# MCXN947_cm33_core0 register map
Vendor: nxp.com; File version: 1.0
CPU: CM33 r2p0, little endian, MPU, FPU, VTOR, 3 interrupt priority bits
Registers are 32-bit, read-write, reset 0x0 unless marked. A register's access mark holds for its fields unless they carry their own. Offsets are from the block's base; [hi:lo] are bit positions; {n}, {i} and the like mark numbered series; 'fields as' and 'values as' point back to an identical list.

## SYSCON0 (part 1 of 2) — SYSCON
Base 0x40000000
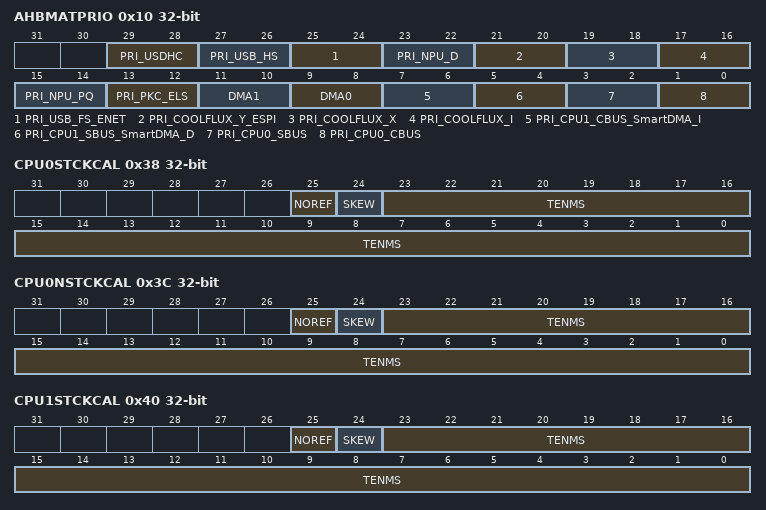
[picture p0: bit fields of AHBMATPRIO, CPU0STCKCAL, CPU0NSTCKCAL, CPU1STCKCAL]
0x10 AHBMATPRIO — AHB Matrix Priority Control
  [all] fields
    {v}=LEVEL{v} (v=0..3)
  [29:28] PRI_USDHC — USDHC bus master priority level
  [27:26] PRI_USB_HS — USB-HS bus master priority level
  [25:24] PRI_USB_FS_ENET — USB-FS and ENET bus master priority level
  [23:22] PRI_NPU_D — NPU D bus master priority level
  [21:20] PRI_COOLFLUX_Y_ESPI — CoolFlux Y bus master priority level
  [19:18] PRI_COOLFLUX_X — CoolFlux X bus master priority level
  [17:16] PRI_COOLFLUX_I — CoolFlux I bus master priority level
  [15:14] PRI_NPU_PQ — NPU O bus and Powerquad bus master priority level
  [13:12] PRI_PKC_ELS — PKC and ELS bus master priority level
  [11:10] DMA1 — DMA1 controller bus master priority level
  [9:8] DMA0 — DMA0 controller bus master priority level
  [7:6] PRI_CPU1_CBUS_SmartDMA_I — CPU1 C-AHB/SmartDMA-I bus master priority level
  [5:4] PRI_CPU1_SBUS_SmartDMA_D — CPU1 S-AHB/SmartDMA-D bus master priority level
  [3:2] PRI_CPU0_SBUS — CPU0 S-AHB bus master priority level
  [1:0] PRI_CPU0_CBUS — CPU0 C-AHB bus master priority level
0x38 CPU0STCKCAL — Secure CPU0 System Tick Calibration
  [25] NOREF — Whether the device provides a reference clock to the processor.
    0=YES_REF (Reference clock is provided); 1=NO_REF (No reference clock is provided)
  [24] SKEW — Whether the TENMS value is exact.
    0=EXACT (TENMS value is exact); 1=INEXACT (TENMS value is not exact or not given)
  [23:0] TENMS — Reload value for 10 ms (100 Hz) timing, subject to system clock skew errors. If the value reads as zero, the calibration value is not known.
0x3C CPU0NSTCKCAL — Non-Secure CPU0 System Tick Calibration
  [25] NOREF — Indicates whether the device provides a reference clock to the processor.
    values as CPU0STCKCAL.NOREF
  [24] SKEW — Indicates whether the TENMS value is exact.
    values as CPU0STCKCAL.SKEW
  [23:0] TENMS — Reload value for 10 ms (100 Hz) timing, subject to system clock skew errors. If the value reads as zero, the calibration value is not known.
0x40 CPU1STCKCAL — System tick calibration for CPU1
  [25] NOREF — Indicates whether the device provides a reference clock to the processor. 0 = reference clock is provided; 1 = no reference clock is provided.
  [24] SKEW — Indicates whether the TENMS value is exact: 0 = TENMS value is exact; 1 = TENMS value is not exact or not given.
  [23:0] TENMS — Reload value for 10 ms (100 Hz) timing, subject to system clock skew errors. If the value reads as zero, the calibration value is not known.
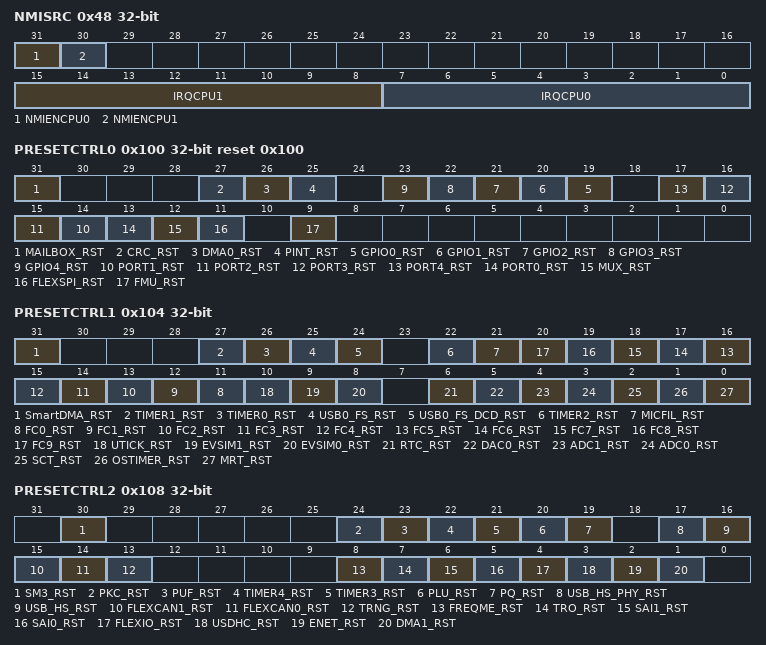
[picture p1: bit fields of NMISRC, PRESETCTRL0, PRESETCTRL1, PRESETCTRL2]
0x48 NMISRC — NMI Source Select
  [31] NMIENCPU0 — Enables the Non-Maskable Interrupt (NMI) source selected by IRQCPU0.
    0=DISABLE; 1=ENABLE
  [30] NMIENCPU1 — Enables the Non-Maskable Interrupt (NMI) source selected by IRQCPU1.
    0=DISABLE; 1=ENABLE
  [15:8] IRQCPU1 — The IRQ number of the interrupt that acts as the Non-Maskable Interrupt (NMI) for CPU1, if enabled by NMIENCPU1.
  [7:0] IRQCPU0 — The IRQ number of the interrupt that acts as the Non-Maskable Interrupt (NMI) for CPU0, if enabled by NMIENCPU0.
0x100 PRESETCTRL0 reset 0x100 (reset mask 0xCEFB13FC) — Peripheral Reset Control 0
  [all] fields
    0=RELEASED (Block is not reset); 1=ASSERTED (Block is reset)
  [31] MAILBOX_RST — Inter-CPU communication Mailbox reset control
  [27] CRC_RST — CRC reset control
  [26] DMA0_RST — DMA0 reset control
  [25] PINT_RST — PINT reset control
  [n+19] GPIO{n}_RST (n=0..4) — GPIO{n} reset control
  [n+13] PORT{n}_RST (n=1..4) — PORT{n} reset control
  [13] PORT0_RST — PORT0 controller reset control
  [12] MUX_RST — INPUTMUX reset control
  [11] FLEXSPI_RST — FlexSPI reset control
  [9] FMU_RST — Flash management unit reset control
0x104 PRESETCTRL1 (reset mask 0xAFFFFF3F) — Peripheral Reset Control 1
  [all] fields
    0=RELEASED (Block is not reset); 1=ASSERTED (Block is reset)
  [31] SmartDMA_RST — SmartDMA reset control
  [27] TIMER1_RST — CTIMER1 reset control
  [26] TIMER0_RST — CTIMER0 reset control
  [25] USB0_FS_RST — USB FS reset control
  [24] USB0_FS_DCD_RST — USB FS DCD reset control
  [22] TIMER2_RST — CTIMER2 reset control
  [21] MICFIL_RST — MICFIL reset control
  [n+11] FC{n}_RST (n=0..9) — LP_FLEXCOMM{n} reset control
  [10] UTICK_RST — UTICK reset control
  [9] EVSIM1_RST — EVSIM1 reset control
  [8] EVSIM0_RST — EVSIM0 reset control
  [6] RTC_RST — RTC reset control
  [5] DAC0_RST — DAC0 reset control
  [4] ADC1_RST — ADC1 reset control
  [3] ADC0_RST — ADC0 reset control
  [2] SCT_RST — SCT reset control
  [1] OSTIMER_RST — OS Event Timer reset control
  [0] MRT_RST — MRT reset control
0x108 PRESETCTRL2 — Peripheral Reset Control 2
  [all] fields
    0=RELEASED (Block is not reset); 1=ASSERTED (Block is reset)
  [30] SM3_RST — SM3 reset control
  [24] PKC_RST — PKC reset control
  [23] PUF_RST — PUF reset control
  [22] TIMER4_RST — CTIMER4 reset control
  [21] TIMER3_RST — CTIMER3 reset control
  [20] PLU_RST — PLU reset control
  [19] PQ_RST — PowerQuad reset control
  [17] USB_HS_PHY_RST — USB HS PHY reset control
  [16] USB_HS_RST — USB HS reset control
  [15] FLEXCAN1_RST — CAN1 reset control
  [14] FLEXCAN0_RST — CAN0 reset control
  [13] TRNG_RST — TRNG reset control
  [8] FREQME_RST — FREQME reset control
  [7] TRO_RST — TRO reset control
  [6] SAI1_RST — SAI1 reset control
  [5] SAI0_RST — SAI0 reset control
  [4] FLEXIO_RST — FLEXIO reset control
  [3] USDHC_RST — uSDHC reset control
  [2] ENET_RST — Ethernet reset control
  [1] DMA1_RST — DMA1 reset control
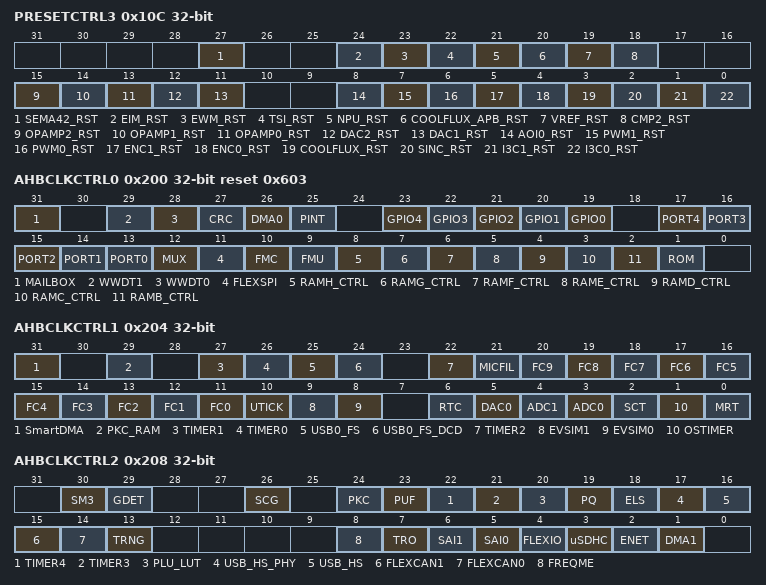
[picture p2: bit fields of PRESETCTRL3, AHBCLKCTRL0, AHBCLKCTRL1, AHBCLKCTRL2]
0x10C PRESETCTRL3 — Peripheral Reset Control 3
  [all] fields
    0=RELEASED (Block is not reset); 1=ASSERTED (Block is reset)
  [27] SEMA42_RST — Semaphore reset control
  [24] EIM_RST — EIM reset control
  [23] EWM_RST — EWM reset control
  [22] TSI_RST — TSI reset control
  [21] NPU_RST — NPU reset control
  [20] COOLFLUX_APB_RST — CoolFlux APB reset control
  [19] VREF_RST — VREF reset control
  [18] CMP2_RST — CMP2 reset control
  [15] OPAMP2_RST — OPAMP2 reset control
  [14] OPAMP1_RST — OPAMP1 reset control
  [13] OPAMP0_RST — OPAMP0 reset control
  [12] DAC2_RST — DAC2 reset control
  [11] DAC1_RST — DAC1 reset control
  [8] AOI0_RST — AOI0 reset control
  [7] PWM1_RST — PWM1 reset control
  [6] PWM0_RST — PWM0 reset control
  [5] ENC1_RST — ENC1 reset control
  [4] ENC0_RST — ENC0 reset control
  [3] COOLFLUX_RST — CoolFlux reset control
  [2] SINC_RST — SINC reset control
  [1] I3C1_RST — I3C1 reset control
  [0] I3C0_RST — I3C0 reset control
{0x120+4i} PRESETCTRLSET[{i}] (i=0..3) wo — Peripheral Reset Control Set
  [31:0] DATA — Data array value, refer to corresponding position in PRESETCTRLn.
{0x140+4i} PRESETCTRLCLR[{i}] (i=0..3) wo — Peripheral Reset Control Clear
  fields as PRESETCTRLSET[0]
0x200 AHBCLKCTRL0 reset 0x603 — AHB Clock Control 0
  [all] fields
    0=DISABLE (Disables clock); 1=ENABLE (Enables clock)
  [31] MAILBOX — Enables the clock for the Inter CPU communication Mailbox.
  [29] WWDT1 — Enables the clock for WWDT1
  [28] WWDT0 — Enables the clock for WWDT0
  [27] CRC — Enables the clock for CRC
  [26] DMA0 — Enables the clock for DMA0
  [25] PINT — Enables the clock for PINT
  [n+19] GPIO{n} (n=0..4) — Enables the clock for GPIO{n}
  [n+13] PORT{n} (n=1..4) — Enables the clock for PORT{n}
  [13] PORT0 — Enables the clock for PORT0 controller
  [12] MUX — Enables the clock for INPUTMUX
  [11] FLEXSPI — Enables the clock for FlexSPI
  [10] FMC — Enables the clock for the Flash Memory Controller
  [9] FMU — Enables the clock for the Flash Management Unit
  [8] RAMH_CTRL — Enables the clock for the RAMH Controller
  [7] RAMG_CTRL — Enables the clock for the RAMG Controller
  [6] RAMF_CTRL — Enables the clock for the RAMF Controller
  [5] RAME_CTRL — Enables the clock for the RAME Controller
  [4] RAMD_CTRL — Enables the clock for the RAMD Controller
  [3] RAMC_CTRL — Enables the clock for the RAMC Controller
  [2] RAMB_CTRL — Enables the clock for the RAMB Controller
  [1] ROM — Enables the clock for the ROM
0x204 AHBCLKCTRL1 — AHB Clock Control 1
  [all] fields
    0=DISABLE (Disables clock); 1=ENABLE (Enables clock)
  [31] SmartDMA — Enables the clock for SmartDMA
  [29] PKC_RAM — Enables the clock for PKC RAM
  [27] TIMER1 — Enables the clock for CTIMER1
  [26] TIMER0 — Enables the clock for CTIMER0
  [25] USB0_FS — Enables the clock for USB-FS
  [24] USB0_FS_DCD — Enables the clock for USB-FS DCD
  [22] TIMER2 — Enables the clock for CTIMER2
  [21] MICFIL — Enables the clock for MICFIL
  [n+11] FC{n} (n=0..9) — Enables the clock for LP_FLEXCOMM{n}
  [10] UTICK — Enables the clock for UTICK
  [9] EVSIM1 — Enables the clock for EVSIM1
  [8] EVSIM0 — Enables the clock for EVSIM0
  [6] RTC — Enables the clock for RTC
  [5] DAC0 — Enables the clock for DAC0
  [4] ADC1 — Enables the clock for ADC1
  [3] ADC0 — Enables the clock for ADC0
  [2] SCT — Enables the clock for SCT
  [1] OSTIMER — Enables the clock for the OS Event Timer
  [0] MRT — Enables the clock for MRT
0x208 AHBCLKCTRL2 — AHB Clock Control 2
  [30] SM3 — Enables the clock for SM3
    0=DISABLE (Disables clock); 1=ENABLE (Enables clock)
  [29] GDET — Enables the clock for GDET0 and GDET1
    0=DISABLE (Disables clock); 1=ENABLE (Enables clock)
  [26] SCG — Enables the clock for SCG
    0=DISABLE (Disables clock); 1=ENABLE (Enables clock)
  [24] PKC — Enables the clock for PKC
    0=DISABLE (Disables clock); 1=ENABLE (Enables clock)
  [23] PUF — Enables the clock for PUF
    0=DISABLE (Disables clock); 1=ENABLE (Enables clock)
  [22] TIMER4 — Enables the clock for CTIMER4
    0=DISABLE (Disables clock); 1=ENABLE (Enables clock)
  [21] TIMER3 — Enables the clock for CTIMER3
    0=DISABLE (Disables clock); 1=ENABLE (Enables clock)
  [20] PLU_LUT — Enables the clock for PLU_LUT
    0=DISABLE (Disables clock); 1=ENABLE (Enables clock)
  [19] PQ — Enables the clock for Powerquad
    0=DISABLE (Disables clock); 1=ENABLE (Enables clock)
  [18] ELS — Enables the clock for ELS
    0=DISABLE (Disables clock); 1=ENABLE (Enables clock)
  [17] USB_HS_PHY — Enables the clock for USB HS PHY
    0=DISABLE (Disables clock); 1=ENABLE (Enables clock)
  [16] USB_HS — Enables the clock for USB HS
    0=DISABLE (Disables clock); 1=ENABLE (Enables clock)
  [15] FLEXCAN1 — Enables the clock for FLEXCAN1
    0=DISABLE (Disables clock); 1=ENABLE (Enables clock)
  [14] FLEXCAN0 — Enables the clock for FLEXCAN0
    0=DISABLE (Disables clock); 1=ENABLE (Enables clock)
  [13] TRNG — Enables the clock for TRNG
    0=DISABLE (Disables clock); 1=ENABLE (Enables clock)
  [8] FREQME — Enables the clock for the Frequency meter
    0=DISABLE (Disables clock); 1=ENABLE (Enables clock)
  [7] TRO — Enables the clock for TRO
    0=DISABLE (Disables clock); 1=ENABLE (Enables clock)
  [6] SAI1 — Enables the clock for SAI1
    0=DISABLE (Disables clock); 1=ENABLE (Enables clock)
  [5] SAI0 — Enables the clock for SAI0
    0=DISABLE (Disables clock); 1=ENABLE (Enables clock)
  [4] FLEXIO — Enables the clock for Flexio
    0=DISABLE (Disables clock); 1=ENABLE (Enable clock)
  [3] uSDHC — Enables the clock for uSDHC
    0=DISABLE (Disables clock); 1=ENABLE (Enables clock)
  [2] ENET — Enables the clock for Ethernet
    0=DISABLE (Disables clock); 1=ENABLE (Enables clock)
  [1] DMA1 — Enables the clock for DMA1
    0=DISABLE (Disables clock); 1=ENABLE (Enables clock)
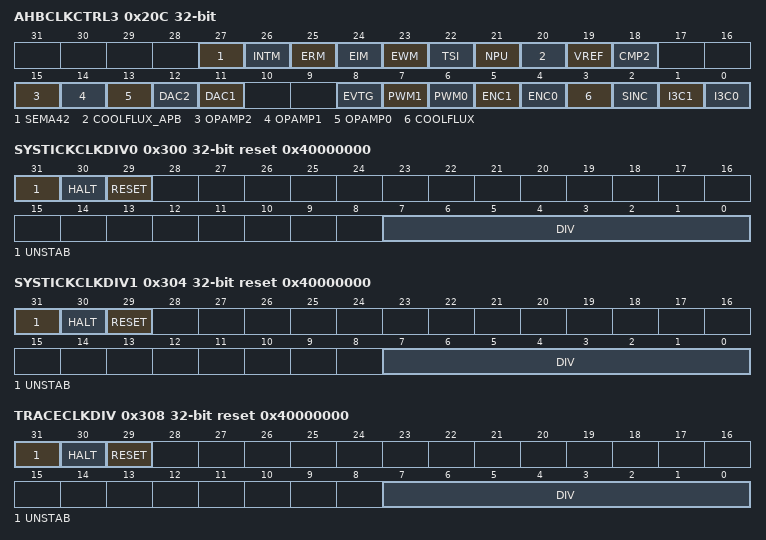
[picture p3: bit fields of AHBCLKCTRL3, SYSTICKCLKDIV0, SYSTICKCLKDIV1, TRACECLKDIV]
0x20C AHBCLKCTRL3 — AHB Clock Control 3
  [27] SEMA42 — Enables the clock for Semaphore
    0=DISABLE (Disables clock); 1=ENABLE (Enables clock)
  [26] INTM — Enables the clock for INTM
    0=DISABLE (Disables clock); 1=ENABLE (Enables clock)
  [25] ERM — Enables the clock for ERM
    0=DISABLE (Disables clock); 1=ENABLE (Enables clock)
  [24] EIM — Enables the clock for EIM
    0=DISABLE (Disables clock); 1=ENABLE (Enables clock)
  [23] EWM — Enables the clock for EWM
    0=DISABLE (Disables clock); 1=ENABLE (Enables clock)
  [22] TSI — Enables the clock for TSI
    0=DISABLE (Disables clock); 1=ENABLE (Enables clock)
  [21] NPU — Enables the clock for NPU
    0=DISABLE (Disables clock); 1=ENABLE (Enables clock)
  [20] COOLFLUX_APB — Enables the clock for CoolFlux APB
    0=DISABLE (Disables clock); 1=ENABLE (Enables clock (CoolFlux needs to be properly programmed before the clock enabled.))
  [19] VREF — Enables the clock for VREF
    0=DISABLE (Disables clock); 1=ENABLE (Enables clock)
  [18] CMP2 — Enables the clock for CMP2
    0=DISABLE (Disables clock); 1=ENABLE (Enables clock)
  [15] OPAMP2 — Enables the clock for OPAMP2
    0=DISABLE (Disables clock); 1=ENABLE (Enables clock)
  [14] OPAMP1 — Enables the clock for OPAMP1
    0=DISABLE (Disables clock); 1=ENABLE (Enables clock)
  [13] OPAMP0 — Enables the clock for OPAMP0
    0=DISABLE (Disables clock); 1=ENABLE (Enables clock)
  [12] DAC2 — Enables the clock for DAC2
    0=DISABLE (Disables clock); 1=ENABLE (Enables clock)
  [11] DAC1 — Enables the clock for DAC1
    0=DISABLE (Disables clock); 1=ENABLE (Enables clock)
  [8] EVTG — Enables the clock for EVTG
    0=DISABLE (Disables clock); 1=ENABLE (Enables clock)
  [7] PWM1 — Enables the clock for PWM1
    0=DISABLE (Disables clock); 1=ENABLE (Enables clock)
  [6] PWM0 — Enables the clock for PWM0
    0=DISABLE (Disables clock); 1=ENABLE (Enables clock)
  [5] ENC1 — Enables the clock for ENC1
    0=DISABLE (Disables clock); 1=ENABLE (Enables clock)
  [4] ENC0 — Enables the clock for ENC0
    0=DISABLE (Disables clock); 1=ENABLE (Enables clock)
  [3] COOLFLUX — Enables the clock for CoolFlux
    0=DISABLE (Disables clock); 1=ENABLE (Enables clock)
  [2] SINC — Enables the clock for SINC
    0=DISABLE (Disables clock); 1=ENABLE (Enables clock)
  [1] I3C1 — Enables the clock for I3C1
    0=DISABLE (Disables clock); 1=ENABLE (Enables clock)
  [0] I3C0 — Enables the clock for I3C0
    0=DISABLE (Disables clock); 1=ENABLE (Enables clock)
{0x220+4i} AHBCLKCTRLSET[{i}] (i=0..3) wo — AHB Clock Control Set
  [31:0] DATA — Data array value
{0x240+4i} AHBCLKCTRLCLR[{i}] (i=0..3) wo — AHB Clock Control Clear
  [31:0] DATA — Data array value
0x260 SYSTICKCLKSEL0 reset 0x7 — CPU0 System Tick Timer Source Select
  [2:0] SEL — Selects the System Tick Timer for CPU0 source
    0=ENUM_0x0 (SYSTICKCLKDIV0 output); 1=ENUM_0x1 (Clk 1 MHz clock); 2=ENUM_0x2 (LP Oscillator clock); {v}=ENUM_{0x0+v} (No clock) (v=3..7)
0x264 SYSTICKCLKSEL1 reset 0x7 — CPU1 System Tick Timer Source Select
  [2:0] SEL — Selects the System Tick Timer for CPU1 source.
    0=ENUM_0x0 (SYSTICKCLKDIV1 output); 1=ENUM_0x1 (Clk 1 MHz clock); 2=ENUM_0x2 (LP Oscillator clock); {v}=ENUM_{0x0+v} (No clock) (v=3..7)
0x268 TRACECLKSEL reset 0x7 — Trace Clock Source Select
  [2:0] SEL — Selects the trace clock source.
    0=ENUM_0x0 (TRACECLKDIV output); 1=ENUM_0x1 (Clk 1 MHz clock); 2=ENUM_0x2 (LP Oscillator clock); {v}=ENUM_{0x0+v} (No clock) (v=3..7)
{0x26C+4i} CTIMERCLKSEL[{i}] (i=0..4) reset 0xF — CTIMER Clock Source Select
  [3:0] SEL — Selects the CTIMER clock source.
    0=ENUM_0x0 (FRO_1M clock); 1=ENUM_0x1 (PLL0 clock); 2=ENUM_0x2 (PLL1_clk0 clock); 3=ENUM_0x3 (FRO_HF clock); 4=ENUM_0x4 (FRO 12MHz clock); 5=ENUM_0x5 (SAI0 MCLK IN clock); 6=ENUM_0x6 (LP Oscillator clock); 7=ENUM_0x7 (No clock); 8=ENUM_0x8 (SAI1 MCLK IN clock); 9=ENUM_0x9 (SAI0 TX_BCLK clock); 10=ENUM_0xA (SAI0 RX_BCLK clock); 11=ENUM_0xB (SAI1 TX_BCLK clock); 12=ENUM_0xC (SAI1 RX_BCLK clock); 13=ENUM_0xD (No clock); 14=ENUM_0xE (No clock); 15=ENUM_0xF (No clock)
0x288 CLKOUTSEL reset 0xF — CLKOUT Clock Source Select
  [3:0] SEL — Selects the CLKOUT clock source.
    0=ENUM_0x0 (Main clock (main_clk)); 1=ENUM_0x1 (PLL0 clock (pll0_clk)); 2=ENUM_0x2 (CLKIN clock (clk_in)); 3=ENUM_0x3 (FRO_HF clock (fro_hf)); 4=ENUM_0x4 (FRO 12 MHz clock (fro_12m)); 5=ENUM_0x5 (PLL1_clk0 clock (pll1_clk)); 6=ENUM_0x6 (LP Oscillator clock (lp_osc)); 7=ENUM_0x7 (USB PLL clock (usb_pll_clk)); {v}=ENUM_{0x0+v} (No clock) (v=8..15)
0x2A4 ADC0CLKSEL reset 0x7 — ADC0 Clock Source Select
  [2:0] SEL — Selects the ADC0 clock source.
    0=ENUM_0x0 (No clock); 1=ENUM_0x1 (PLL0 clock); 2=ENUM_0x2 (FRO_HF clock); 3=ENUM_0x3 (FRO 12 MHz clock); 4=ENUM_0x4 (Clk_in); 5=ENUM_0x5 (PLL1_clk0 clock); 6=ENUM_0x6 (USB PLL clock); 7=ENUM_0x7 (No clock)
0x2A8 USB0CLKSEL reset 0x7 — USB-FS Clock Source Select
  [2:0] SEL — Selects the USB-FS clock source.
    0=ENUM_0x0 (No clock); 1=ENUM_0x1 (PLL0 clock); 2=ENUM_0x2 (No clock); 3=ENUM_0x3 (Clk 48 MHz clock); 4=ENUM_0x4 (Clk_in); 5=ENUM_0x5 (PLL1_clk0 clock); 6=ENUM_0x6 (USB PLL clock); 7=ENUM_0x7 (No clock)
{0x2B0+4i} FCCLKSEL[{i}] (i=0..9) reset 0x7 — LP_FLEXCOMM Clock Source Select for Fractional Rate Divider
  [2:0] SEL — Selects the LP_FLEXCOMM clock source for Fractional Rate Divider.
    0=ENUM_0x0 (No clock); 1=ENUM_0x1 (PLL divided clock); 2=ENUM_0x2 (FRO 12 MHz clock); 3=ENUM_0x3 (fro_hf_div clock); 4=ENUM_0x4 (CLK_1MHz clock); 5=ENUM_0x5 (USB PLL clock); 6=ENUM_0x6 (LP Oscillator clock); 7=ENUM_0x7 (No clock)
0x2F0 SCTCLKSEL reset 0xF — SCTimer/PWM Clock Source Select
  [3:0] SEL — Selects the SCTimer/PWM clock source.
    0=ENUM_0x0 (No clock); 1=ENUM_0x1 (PLL0 clock); 2=ENUM_0x2 (CLKIN clock); 3=ENUM_0x3 (FRO_HF clock); 4=ENUM_0x4 (PLL1_clk0 clock); 5=ENUM_0x5 (SAI0 MCLK_IN clock); 6=ENUM_0x6 (USB PLL clock); 7=ENUM_0x7 (No clock); 8=ENUM_0x8 (SAI1 MCLK_IN clock); {v}=ENUM_{0x0+v} (No clock) (v=9..15)
0x300 SYSTICKCLKDIV0 reset 0x40000000 — CPU0 System Tick Timer Divider
  [31] UNSTAB ro — Divider status flag
    0=STABLE (Divider clock is stable); 1=ONGOING (Clock frequency is not stable)
  [30] HALT — Halts the divider counter
    0=RUN (Divider clock is running); 1=HALT (Divider clock is stopped)
  [29] RESET — Resets the divider counter
    0=RELEASED (Divider is not reset); 1=ASSERTED (Divider is reset.)
  [7:0] DIV — Clock divider value
0x304 SYSTICKCLKDIV1 reset 0x40000000 — CPU1 System Tick Timer Divider
  [31] UNSTAB ro — Divider status flag
    values as SYSTICKCLKDIV0.UNSTAB
  [30] HALT — Halts the divider counter
    values as SYSTICKCLKDIV0.HALT
  [29] RESET — Resets the divider counter
    0=RELEASED (Divider is not reset); 1=ASSERTED (Divider is reset)
  [7:0] DIV — Clock divider value
0x308 TRACECLKDIV reset 0x40000000 — TRACE Clock Divider
  fields as SYSTICKCLKDIV1
0x350 TSICLKSEL reset 0x7 — TSI Function Clock Source Select
  [2:0] SEL — Selects the TSI function clock source.
    0=ENUM_0x0 (No clock); 1=ENUM_0x1 (No clock); 2=ENUM_0x2 (clk_in); 3=ENUM_0x3 (No clock); 4=ENUM_0x4 (FRO_12Mhz clock); 5=ENUM_0x5 (No clock); 6=ENUM_0x6 (No clock); 7=ENUM_0x7 (No clock)
0x360 SINCFILTCLKSEL reset 0x7 — SINC FILTER Function Clock Source Select
  [2:0] SEL — Selects the SINC FILTER function clock source.
    0=ENUM_0x0 (No clock); 1=ENUM_0x1 (PLL0 clock); 2=ENUM_0x2 (clk_in); 3=ENUM_0x3 (FRO_HF clock); 4=ENUM_0x4 (FRO_12Mhz clock); 5=ENUM_0x5 (PLL1_clk0 clock); 6=ENUM_0x6 (USB PLL clock); 7=ENUM_0x7 (No clock)
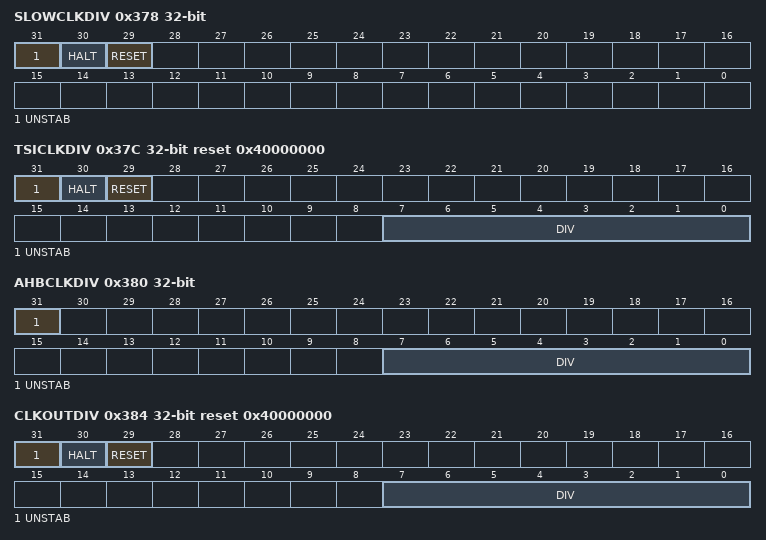
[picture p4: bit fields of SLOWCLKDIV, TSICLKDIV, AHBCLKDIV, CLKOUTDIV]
0x378 SLOWCLKDIV — SLOW_CLK Clock Divider
  [31] UNSTAB ro — Divider status flag
    values as SYSTICKCLKDIV0.UNSTAB
  [30] HALT — Halts the divider counter
    values as SYSTICKCLKDIV0.HALT
  [29] RESET — Resets the divider counter
    values as SYSTICKCLKDIV1.RESET
0x37C TSICLKDIV reset 0x40000000 — TSI Function Clock Divider
  [31] UNSTAB ro — Divider status flag
    values as SYSTICKCLKDIV0.UNSTAB
  [30] HALT — Halts the divider counter
    values as SYSTICKCLKDIV0.HALT
  [29] RESET — Resets the divider counter
    values as SYSTICKCLKDIV1.RESET
  [7:0] DIV — Clock divider value:
0x380 AHBCLKDIV — System Clock Divider
  [31] UNSTAB ro — Divider status flag
    values as SYSTICKCLKDIV0.UNSTAB
  [7:0] DIV — Clock divider value
0x384 CLKOUTDIV reset 0x40000000 — CLKOUT Clock Divider
  fields as SYSTICKCLKDIV1
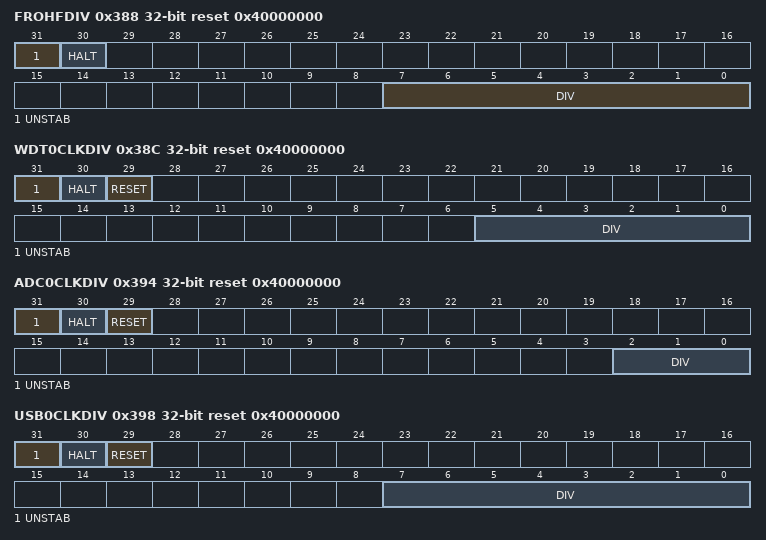
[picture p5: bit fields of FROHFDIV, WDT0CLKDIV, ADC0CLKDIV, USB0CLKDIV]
0x388 FROHFDIV reset 0x40000000 — FRO_HF_DIV Clock Divider
  [31] UNSTAB ro — Divider status flag
    values as SYSTICKCLKDIV0.UNSTAB
  [30] HALT ro — Halts the divider counter
    0=RUN (Divider clock is running, this bit is set to 0 when the register is written.); 1=HALT (Divider clock is stopped)
  [7:0] DIV — Clock divider value
0x38C WDT0CLKDIV reset 0x40000000 — WDT0 Clock Divider
  [31] UNSTAB ro — Divider status flag
    values as SYSTICKCLKDIV0.UNSTAB
  [30] HALT — Halts the divider counter
    values as SYSTICKCLKDIV0.HALT
  [29] RESET — Resets the divider counter
    values as SYSTICKCLKDIV1.RESET
  [5:0] DIV — Clock divider value
0x394 ADC0CLKDIV reset 0x40000000 — ADC0 Clock Divider
  [31] UNSTAB ro — Divider status flag
    values as SYSTICKCLKDIV0.UNSTAB
  [30] HALT — Halts the divider counter
    values as SYSTICKCLKDIV0.HALT
  [29] RESET — Resets the divider counter
    values as SYSTICKCLKDIV1.RESET
  [2:0] DIV — Clock divider value
0x398 USB0CLKDIV reset 0x40000000 — USB-FS Clock Divider
  fields as SYSTICKCLKDIV1
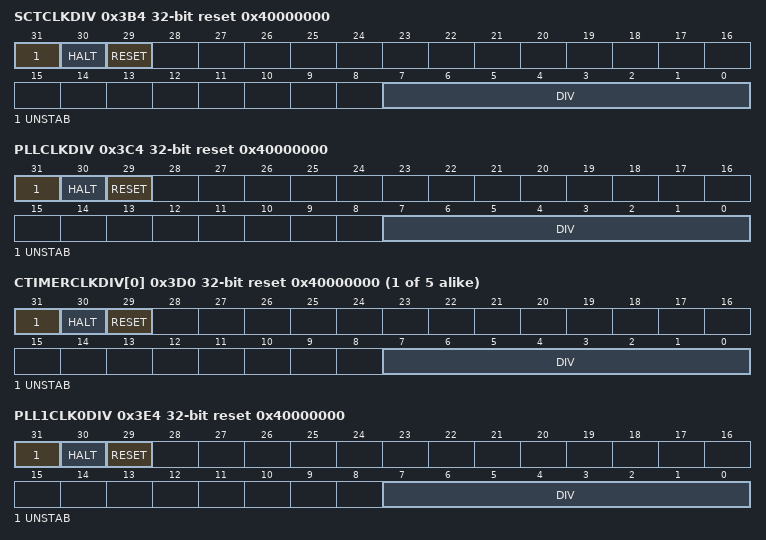
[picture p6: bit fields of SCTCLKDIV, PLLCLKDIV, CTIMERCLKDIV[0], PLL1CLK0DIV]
0x3B4 SCTCLKDIV reset 0x40000000 — SCT/PWM Clock Divider
  fields as SYSTICKCLKDIV1
0x3C4 PLLCLKDIV reset 0x40000000 — PLL Clock Divider
  fields as SYSTICKCLKDIV1
{0x3D0+4i} CTIMERCLKDIV[{i}] (i=0..4) reset 0x40000000 — CTimer Clock Divider
  [31] UNSTAB — Divider status flag
    0=ENABLE (Stable divider clock); 1=DISABLE (Unstable clock frequency)
  [30] HALT — Halts the divider counter
    0=ENABLE (Divider clock is running); 1=DISABLE (Divider clock has stopped)
  [29] RESET — Resets the divider counter
    0=DISABLE (Divider is not reset); 1=ENABLE (Divider is reset)
  [7:0] DIV — Clock divider value
0x3E4 PLL1CLK0DIV reset 0x40000000 — PLL1 Clock 0 Divider
  fields as SYSTICKCLKDIV1
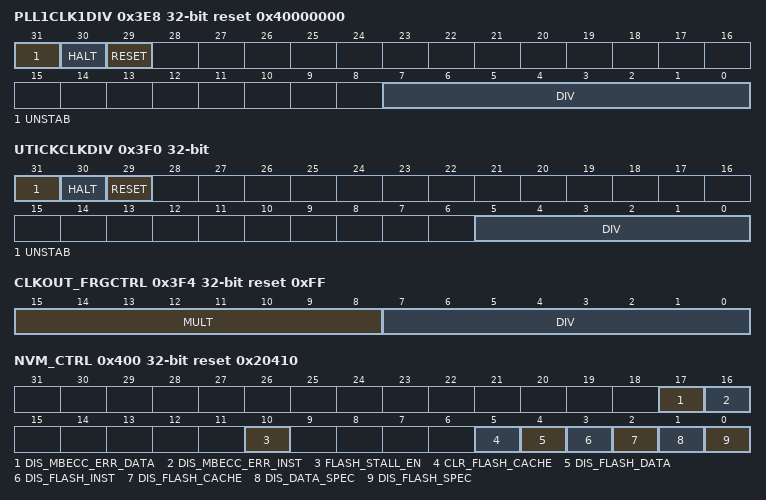
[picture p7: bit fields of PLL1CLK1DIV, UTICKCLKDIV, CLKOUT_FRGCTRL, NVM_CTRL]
0x3E8 PLL1CLK1DIV reset 0x40000000 — PLL1 Clock 1 Divider
  fields as SYSTICKCLKDIV1
0x3F0 UTICKCLKDIV — UTICK Clock Divider
  fields as WDT0CLKDIV
0x3F4 CLKOUT_FRGCTRL reset 0xFF — CLKOUT FRG Control
  [15:8] MULT — Numerator value
  [7:0] DIV — Divider value
0x3FC CLKUNLOCK — Clock Configuration Unlock
  [0] UNLOCK — Controls clock configuration registers access (for example, xxxDIV, xxxSEL)
    0=ENABLE (Updates are allowed to all clock configuration registers); 1=FREEZE (Freezes all clock configuration registers update)
0x400 NVM_CTRL reset 0x20410 — NVM Control
  [17] DIS_MBECC_ERR_DATA — Bus error on data multi-bit ECC error control If DIS_MBECC_ERR_DATA and/or DIS_MBECC_INST are set, then speculation will not be enabled, even if this bit is cleared
    0=ENABLE (Enables bus error on multi-bit ECC error for data); 1=DISABLE (Disables bus error on multi-bit ECC error for data)
  [16] DIS_MBECC_ERR_INST — Bus error on instruction multi-bit ECC error control If DIS_MBECC_ERR_DATA and/or DIS_MBECC_INST are set, then speculation will not be enabled, even if this bit is cleared
    0=ENABLE (Enables bus error on multi-bit ECC error for instruction); 1=DISABLE (Disables bus error on multi-bit ECC error for instruction)
  [10] FLASH_STALL_EN — FLASH stall on busy control
    0=ENABLE (No stall on FLASH busy); 1=DISABLE (Stall on FLASH busy)
  [5] CLR_FLASH_CACHE — Clear flash cache control
    0=ENABLE (No clear flash cache); 1=DISABLE (Clears flash cache)
  [4] DIS_FLASH_DATA — Flash data cache control
    0=ENABLE (Enables flash data cache when DIS_FLASH_CACHE=0); 1=DISABLE (Disables flash data cache)
  [3] DIS_FLASH_INST — Flash instruction cache control
    0=ENABLE (Enables flash instruction cache when DIS_FLASH_CACHE=0); 1=DISABLE (Disables flash instruction cache)
  [2] DIS_FLASH_CACHE — Flash cache control
    0=ENABLE (Enables flash cache); 1=DISABLE (Disables flash cache)
  [1] DIS_DATA_SPEC — Flash data speculation control
    0=ENABLE (Enables data speculation); 1=DISABLE (Disables data speculation)
  [0] DIS_FLASH_SPEC — Flash speculation control
    0=ENABLE (Enables flash speculation); 1=DISABLE (Disables flash speculation)
0x404 ROMCR — ROM Wait State
  [0] ROM_WAIT — ROM waiting Arm core and other masters for one cycle
    0=DISABLE (Disabled); 1=Enabled
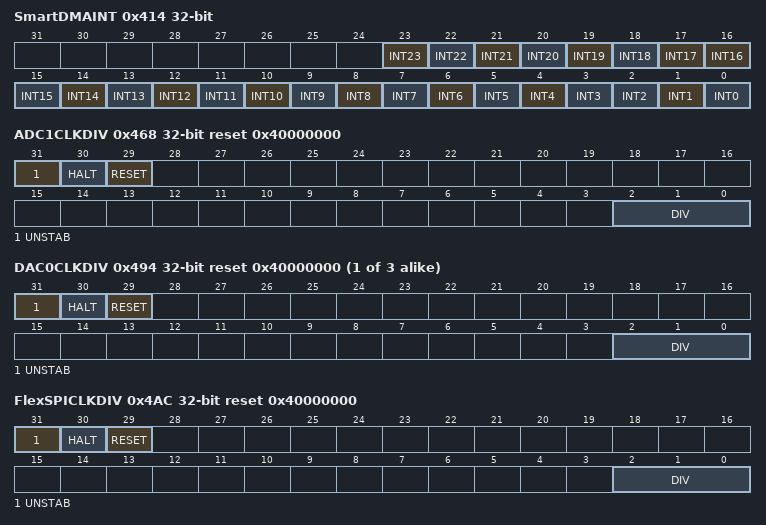
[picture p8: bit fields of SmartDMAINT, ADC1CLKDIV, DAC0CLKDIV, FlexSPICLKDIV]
0x414 SmartDMAINT — SmartDMA Interrupt Hijack
  [all] fields
    0=DISABLE; 1=ENABLE
  [23] INT23 — SmartDMA hijack NVIC IRQ77
  [22] INT22 — SmartDMA hijack NVIC IRQ67
  [21] INT21 — SmartDMA hijack NVIC IRQ66
  [20] INT20 — SmartDMA hijack NVIC IRQ51
  [19] INT19 — SmartDMA hijack NVIC IRQ50
  [18] INT18 — SmartDMA hijack NVIC IRQ47
  [17] INT17 — SmartDMA hijack NVIC IRQ45
  [n] INT{n} (n=3..16) — SmartDMA hijack NVIC IRQ{n+26}
  [2] INT2 — SmartDMA hijack NVIC IRQ18
  [1] INT1 — SmartDMA hijack NVIC IRQ17
  [0] INT0 — SmartDMA hijack NVIC IRQ1
0x464 ADC1CLKSEL reset 0x7 — ADC1 Clock Source Select
  [2:0] SEL — Selects the ADC1 clock source
    0=ENUM_0x0 (No clock); 1=ENUM_0x1 (PLL0 clock); 2=ENUM_0x2 (FRO_HF clock); 3=ENUM_0x3 (FRO 12 MHz clock); 4=ENUM_0x4 (Clk_in clock); 5=ENUM_0x5 (PLL1_clk0 clock); 6=ENUM_0x6 (USB PLL clock); 7=ENUM_0x7 (No clock)
0x468 ADC1CLKDIV reset 0x40000000 — ADC1 Clock Divider
  fields as ADC0CLKDIV
0x470 RAM_INTERLEAVE — Control PKC RAM Interleave Access
  [0] INTERLEAVE — Controls PKC RAM access for PKC RAM 0 and PKC RAM 1
    0=NORMAL (RAM access to PKC RAM 0 and PKC RAM 1 is consecutive.); 1=INTERLEAVE (RAM access to PKC RAM 0 and PKC RAM 1 is interleaved. This setting is need for PKC L0 memory access.)
{0x490+8i} DAC{i}CLKSEL reset 0x7 (i=0..2) — DAC{i} Functional Clock Selection
  [2:0] SEL — Selects the DAC clock source
    0=ENUM_0x0 (No clock); 1=ENUM_0x1 (PLL0 clock); 2=ENUM_0x2 (Clk_in); 3=ENUM_0x3 (FRO_HF); 4=ENUM_0x4 (FRO_12M); 5=ENUM_0x5 (PLL1_clk0 clock); 6=ENUM_0x6 (No clock); 7=ENUM_0x7 (No clock)
{0x494+8i} DAC{i}CLKDIV reset 0x40000000 (i=0..2) — DAC{i} functional clock divider
  fields as ADC0CLKDIV
0x4A8 FlexSPICLKSEL reset 0xF — FlexSPI Clock Selection
  [3:0] SEL — Selects the FlexSPI clock
    0=No clock; 1=PLL0 clock; 2=No clock; 3=FRO_HF; 4=No clock; 5=pll1_clock; 6=USB PLL clock; {v}=No clock (v=7..15)
0x4AC FlexSPICLKDIV reset 0x40000000 — FlexSPI Clock Divider
  fields as ADC0CLKDIV
0x52C PLLCLKDIVSEL reset 0x7 — PLL Clock Divider Clock Selection
  [2:0] SEL — Selects the PLL Clock Divider source clock
    0=PLL0 clock; 1=pll1_clk0; {v}=No clock (v=2..7)
0x530 I3C0FCLKSEL reset 0x7 — I3C0 Functional Clock Selection
  [2:0] SEL — Selects the I3C0 clock
    0=No clock; 1=PLL0 clock; 2=CLKIN clock; 3=FRO_HF clock; 4=No clock; 5=PLL1_clk0 clock; 6=USB PLL clock; 7=No clock
0x534 I3C0FCLKSTCSEL reset 0x7 — I3C0 FCLK_STC Clock Selection
  [2:0] SEL — Selects the I3C0 Time Control clock
    0=I3C0 functional clock I3C0FCLK; 1=FRO_1M clock; {v}=No clock (v=2..7)
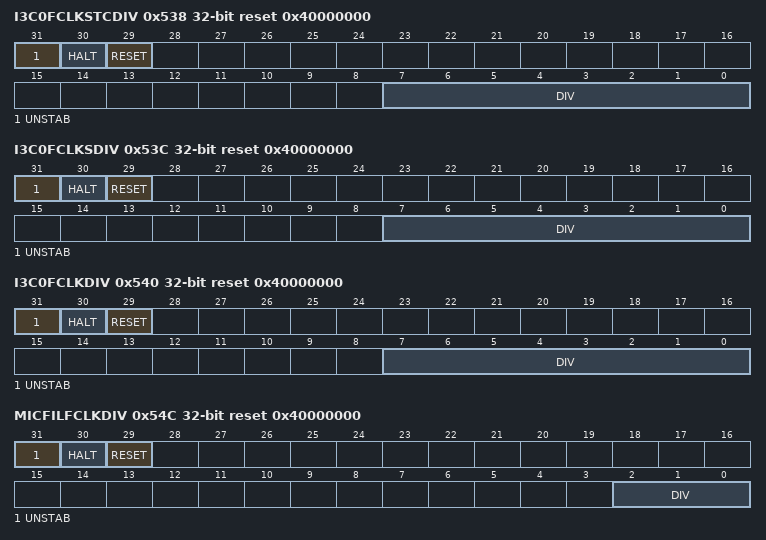
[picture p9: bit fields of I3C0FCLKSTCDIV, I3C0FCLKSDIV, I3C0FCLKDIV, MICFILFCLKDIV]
0x538 I3C0FCLKSTCDIV reset 0x40000000 — I3C0 FCLK_STC Clock Divider
  fields as SYSTICKCLKDIV1
0x53C I3C0FCLKSDIV reset 0x40000000 — I3C0 FCLK Slow Clock Divider
  fields as SYSTICKCLKDIV1
0x540 I3C0FCLKDIV reset 0x40000000 — I3C0 Functional Clock FCLK Divider
  fields as SYSTICKCLKDIV1
0x544 I3C0FCLKSSEL — I3C0 FCLK Slow Selection
  [2:0] SEL — Selects the I3C FCLK Slow clock
    0=FRO_1M clock; {v}=No clock (v=1..7)
0x548 MICFILFCLKSEL reset 0xF — MICFIL Clock Selection
  [3:0] SEL — Selects the MICFIL clock
    0=FRO_12M clock; 1=PLL0 clock; 2=CLKIN clock; 3=FRO_HF clock; 4=PLL1_clk0 clock; 5=SAI0_MCLK clock; 6=USB PLL clock; 7=No clock; 8=SAI1_MCLK clock; {v}=No clock (v=9..15)
0x54C MICFILFCLKDIV reset 0x40000000 — MICFIL Clock Division
  fields as ADC0CLKDIV
0x558 uSDHCCLKSEL reset 0x7 — uSDHC Clock Selection
  [2:0] SEL — Selects the uSDHC clock
    0=No clock; 1=PLL0 clock; 2=CLKIN clock; 3=FRO_HF clock; 4=FRO_12M clock; 5=pll1_clk1 clock; 6=USB PLL clock; 7=No clock
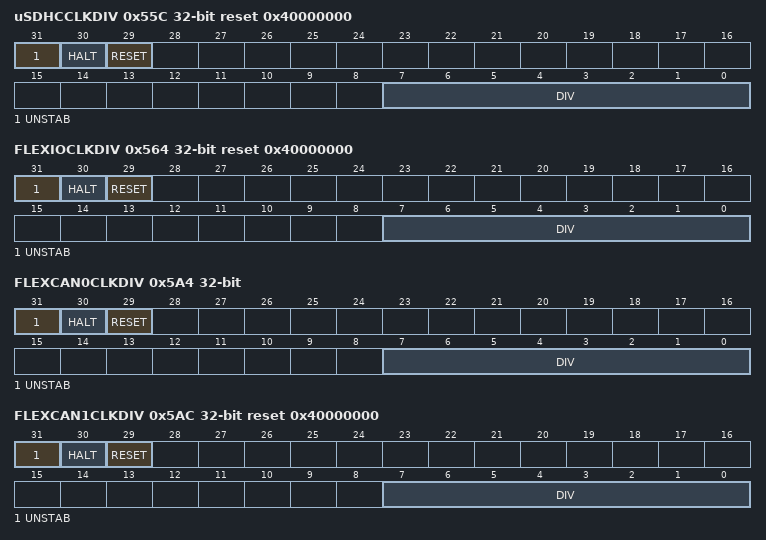
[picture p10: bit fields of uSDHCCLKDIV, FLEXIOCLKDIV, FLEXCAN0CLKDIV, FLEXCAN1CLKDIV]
0x55C uSDHCCLKDIV reset 0x40000000 — uSDHC Function Clock Divider
  fields as SYSTICKCLKDIV1
0x560 FLEXIOCLKSEL reset 0x7 — FLEXIO Clock Selection
  [2:0] SEL — Selects the FLEXIO clock
    0=No clock; 1=PLL0 clock; 2=CLKIN clock; 3=FRO_HF clock; 4=FRO_12M clock; 5=PLL1_clk0 clock; 6=USB PLL clock; 7=No clock
0x564 FLEXIOCLKDIV reset 0x40000000 — FLEXIO Function Clock Divider
  fields as SYSTICKCLKDIV1
0x5A0 FLEXCAN0CLKSEL reset 0x7 — FLEXCAN0 Clock Selection
  [2:0] SEL — Selects the FLEXCAN0 clock
    values as I3C0FCLKSEL.SEL
0x5A4 FLEXCAN0CLKDIV — FLEXCAN0 Function Clock Divider
  fields as SYSTICKCLKDIV1
0x5A8 FLEXCAN1CLKSEL reset 0x7 — FLEXCAN1 Clock Selection
  [2:0] SEL — Selects the FLEXCAN1 clock
    values as I3C0FCLKSEL.SEL
0x5AC FLEXCAN1CLKDIV reset 0x40000000 — FLEXCAN1 Function Clock Divider
  fields as SYSTICKCLKDIV1
0x5B0 ENETRMIICLKSEL reset 0x7 — Ethernet RMII Clock Selection
  [2:0] SEL — Selects the Ethernet RMII clock
    0=No clock; 1=PLL0 clock; 2=CLKIN clock; 3=No clock; 4=No clock; 5=PLL1_clk0 clock; 6=No clock; 7=No clock
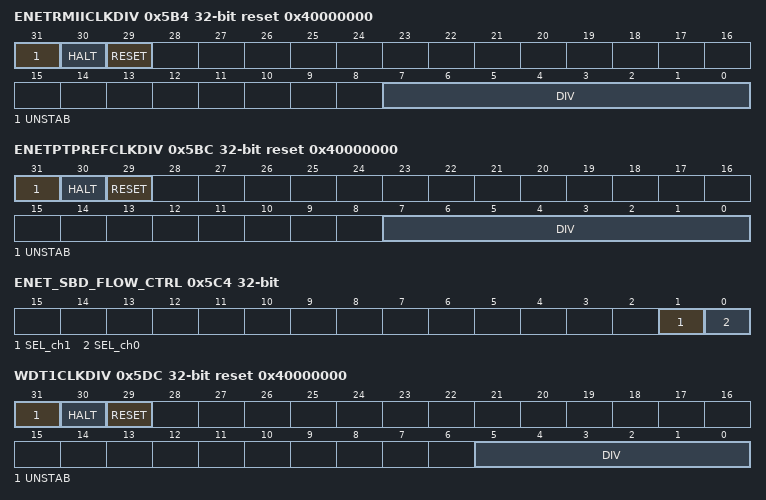
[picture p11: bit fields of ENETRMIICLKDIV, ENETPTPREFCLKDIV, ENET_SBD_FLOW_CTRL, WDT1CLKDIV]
0x5B4 ENETRMIICLKDIV reset 0x40000000 — Ethernet RMII Function Clock Divider
  fields as SYSTICKCLKDIV1
0x5B8 ENETPTPREFCLKSEL reset 0x7 — Ethernet PTP REF Clock Selection
  [2:0] SEL — Selects the Ethernet PTP REF clock
    0=No clock; 1=PLL0 clock; 2=CLKIN clock; 3=No clock; 4=enet0_tx_clk clock; 5=pll1_clk1 clock; 6=No clock; 7=No clock
0x5BC ENETPTPREFCLKDIV reset 0x40000000 — Ethernet PTP REF Function Clock Divider
  fields as SYSTICKCLKDIV1
0x5C0 ENET_PHY_INTF_SEL — Ethernet PHY Interface Select
  [2] PHY_SEL — Selects the PHY interface
    0=MII (Selects MII PHY Interface); 1=RMII (Selects RMII PHY Interface)
0x5C4 ENET_SBD_FLOW_CTRL — Sideband Flow Control
  [1] SEL_ch1 — Sideband Flow Control for channel1
    0=DISABLE (No trigger flow control); 1=ENABLE (Trigger flow control)
  [0] SEL_ch0 — Sideband Flow Control for channel0
    values as SEL_ch1
0x5D4 EWM0CLKSEL reset 0x1 — EWM0 Clock Selection
  [0] SEL — Selects the EWM0 clock
    0=clk_16k[2]; 1=xtal32k[2]
0x5D8 WDT1CLKSEL reset 0x3 — WDT1 Clock Selection
  [1:0] SEL — Selects the WDT1 clock
    0=FRO16K clock 2; 1=fro_hf_div clock; 2=clk_1m clock; 3=clk_1m clock
0x5DC WDT1CLKDIV reset 0x40000000 — WDT1 Function Clock Divider
  fields as WDT0CLKDIV
0x5E0 OSTIMERCLKSEL reset 0x3 — OSTIMER Clock Selection
  [1:0] SEL — Selects the OS Event Timer clock
    0=clk_16k[2]; 1=xtal32k[2]; 2=clk_1m clock; 3=No clock
0x5F0 CMP0FCLKSEL reset 0x7 — CMP0 Function Clock Selection
  [2:0] SEL — Selects the CMP0 function clock
    0=No clock; 1=PLL0 clock; 2=FRO_HF clock; 3=FRO_12M clock; 4=CLKIN clock; 5=PLL1_clk0 clock; 6=USB PLL clock; 7=No clock
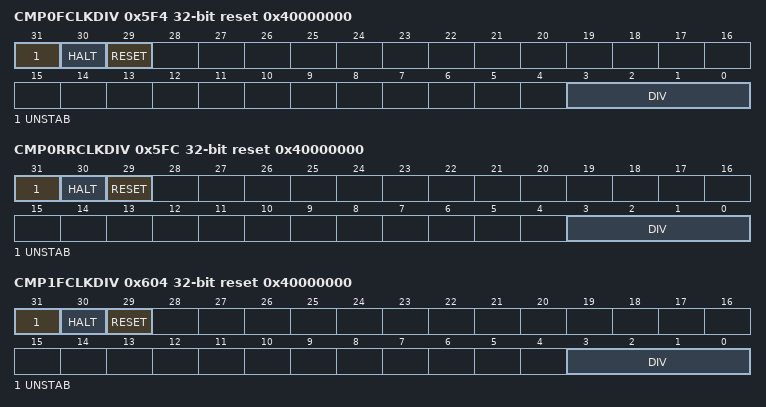
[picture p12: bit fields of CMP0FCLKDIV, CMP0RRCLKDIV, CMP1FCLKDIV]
0x5F4 CMP0FCLKDIV reset 0x40000000 — CMP0 Function Clock Divider
  [31] UNSTAB ro — Divider status flag
    values as SYSTICKCLKDIV0.UNSTAB
  [30] HALT — Halts the divider counter
    values as SYSTICKCLKDIV0.HALT
  [29] RESET — Resets the divider counter
    values as SYSTICKCLKDIV1.RESET
  [3:0] DIV — Clock divider value
0x5F8 CMP0RRCLKSEL reset 0x7 — CMP0 Round Robin Clock Selection
  [2:0] SEL — Selects the CMP0 round robin clock
    values as CMP0FCLKSEL.SEL
0x5FC CMP0RRCLKDIV reset 0x40000000 — CMP0 Round Robin Clock Divider
  fields as CMP0FCLKDIV
0x600 CMP1FCLKSEL reset 0x7 — CMP1 Function Clock Selection
  [2:0] SEL — Selects the CMP1 function clock
    values as CMP0FCLKSEL.SEL
0x604 CMP1FCLKDIV reset 0x40000000 — CMP1 Function Clock Divider
  fields as CMP0FCLKDIV
0x608 CMP1RRCLKSEL reset 0x7 — CMP1 Round Robin Clock Source Select
  [2:0] SEL — Selects the CMP1 round robin clock
    values as CMP0FCLKSEL.SEL
